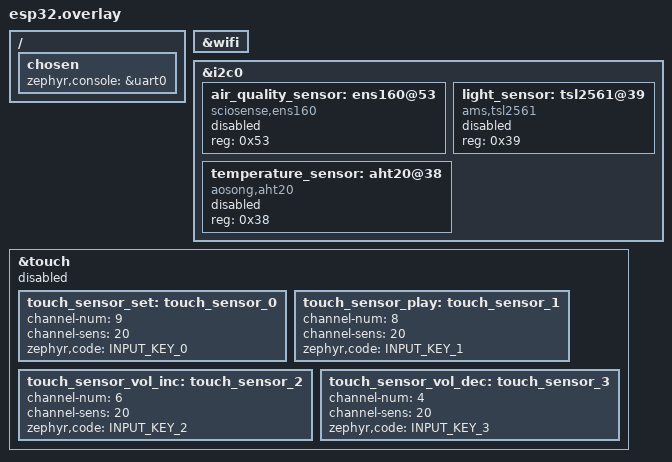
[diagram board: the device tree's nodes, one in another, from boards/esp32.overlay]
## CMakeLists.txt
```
#-------------------------------------------------------------------------------
# Zephyr Example Application
#
# Copyright (c) 2021 Nordic Semiconductor ASA
# SPDX-License-Identifier: Apache-2.0

cmake_minimum_required(VERSION 3.20.3)

#-------------------------------------------
# Overlay File
set(DTC_OVERLAY_FILE "boards/esp32.overlay")
set(CONFIG_APPLICATION_DEFINED_SYSCALL  TRUE)

# Define additional overlay configuration files
# set(OVERLAY_CONFIG "overlay-debug.conf; overlay-enterprise-variable-bufs.conf; overlay-enterprise.conf;")

# Pass configuration files to the build system
# set_property(GLOBAL PROPERTY OVERLAY_CONFIG "${OVERLAY_CONFIG}")

#-------------------------------------------
# Include Zephyr SDK
find_package(Zephyr REQUIRED HINTS $ENV{ZEPHYR_BASE})

#-------------------------------------------
# Project
project(app)

#-------------------------------------------
# Source Files
# Main
target_sources(app PRIVATE src/main.cpp)

# My Logger
target_sources(app PRIVATE src/myLogger/myLogger.cpp)

# Manager Factory
target_sources(app PRIVATE src/managerFactory/managerFactory.cpp)

# Network Manager
target_sources(app PRIVATE src/networkManager/networkManager.cpp)

# Network Time Manager
target_sources(app PRIVATE src/networkTimeManager/networkTimeManager.cpp)

# Ping Manager
target_sources(app PRIVATE src/pingManager/pingManager.cpp)

# Sensor Manager
target_sources(app PRIVATE src/sensorManager/sensorManager.cpp)

# Sensors
target_sources(app PRIVATE src/sensors/temperatureSensor.cpp)
target_sources(app PRIVATE src/sensors/lightSensor.cpp)

# Socket
target_sources(app PRIVATE src/sockets/sockets.cpp)

# Socket Manager
target_sources(app PRIVATE src/socketManager/socketManager.cpp)

# Socket Strategy
target_sources(app PRIVATE src/socketStrategy/socketStrategy.cpp)

# Wifi Manager
target_sources(app PRIVATE src/wifiManager/wifiManager.cpp)
target_sources(app PRIVATE src/wifiManager/wifiManagerHandlers.cpp)

# Wifi State Machine
target_sources(app PRIVATE src/wifiSM/wifiContext.cpp)
target_sources(app PRIVATE src/wifiSM/wifiStateConnected.cpp)
target_sources(app PRIVATE src/wifiSM/wifiStateConnecting.cpp)
target_sources(app PRIVATE src/wifiSM/wifiStateDisconnected.cpp)
target_sources(app PRIVATE src/wifiSM/wifiStateError.cpp)
target_sources(app PRIVATE src/wifiSM/wifiStateIdle.cpp)

#-------------------------------------------
# Include Directories
# zephyr_syscall_include_directories(./../include/app/drivers/)
# zephyr_include_directories(./../include)
# zephyr_include_directories(./../include/app/drivers/)

# My Logger
target_include_directories(app PRIVATE src/myLogger)

# Network Manager
target_include_directories(app PRIVATE src/networkManager)

# Network Time Manager
target_include_directories(app PRIVATE src/networkTimeManager)

# Ping Manager
target_include_directories(app PRIVATE src/pingManager)

# Sensor Manager
target_include_directories(app PRIVATE src/sensorManager)

# Sensors
target_include_directories(app PRIVATE src/sensors)

# Sockets
target_include_directories(app PRIVATE src/sockets)

# Socket Manager
target_include_directories(app PRIVATE src/socketManager)
target_include_directories(app PRIVATE src/socketStrategy)

# Wifi Manager
target_include_directories(app PRIVATE src/managerFactory)
target_include_directories(app PRIVATE src/wifiManager)
target_include_directories(app PRIVATE src/wifiSM)

target_include_directories(app PRIVATE ./../include/)
target_include_directories(app PRIVATE ./../include/app/)
target_include_directories(app PRIVATE ./../include/app/drivers)
# target_include_directories(app PRIVATE ./../include/utils/myLogger)

#-------------------------------------------
# System Calls Header Files
# zephyr_syscall_header_ifdef (./../include/app/drivers/my_syscall.h)
# zephyr_syscall_header (./../include/app/drivers/blink.h)

#-------------------------------------------
# Libraries
target_link_libraries(app PRIVATE zephyr_interface)

#-------------------------------------------
# Compiler Options
target_compile_definitions(app PRIVATE
    WIFI_SSID="$ENV{WIFI_SSID}"
    WIFI_PASSWORD="$ENV{WIFI_PASSWORD}"
    MY_REMOTE="$ENV{MY_REMOTE}"
    MY_LOCAL="$ENV{MY_LOCAL}"
)

#-------------------------------------------
# GraphViz
add_custom_target(graphviz
    COMMAND ${CMAKE_COMMAND} "--graphviz=dependencyGraph.dot" .
    WORKING_DIRECTORY "${CMAKE_BINARY_DIR}"
)
```

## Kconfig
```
# Copyright (c) 2021 Nordic Semiconductor ASA
# SPDX-License-Identifier: Apache-2.0
#
# This file is the application Kconfig entry point. All application Kconfig
# options can be defined here or included via other application Kconfig files.
# You can browse these options using the west targets menuconfig (terminal) or
# guiconfig (GUI).

# For Configuring Zephyr
menu "Zephyr"
source "Kconfig.zephyr"
endmenu

# For Configuring Custom Drivers/Libraries
menu "Custom Drivers/Libraries"
rsource "../Kconfig"
endmenu

# For Creating Logging Module for Application
module = APP
module-str = APP
source "subsys/logging/Kconfig.template.log_config"
```

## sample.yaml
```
# This file is provided so that the application can be compiled using Twister,
# the Zephyr testing tool. In this file, multiple combinations can be specified,
# so that you can easily test all of them locally or in CI.
sample:
  description: Example application
  name: example-application
common:
  build_only: true
  integration_platforms:
    - esp32
build:
  kconfig: Kconfig
  cmake: .
  board: esp32
  harness: net
  settings:
    board_root: boards/
    dts_root: .
  tags:
    - net
    - wifi
tests:
  sample.net.wifi.esp32:
    extra_args:
      - CONFIG_BUILD_ONLY_NO_BLOBS=y
  app.default: {}
  app.debug:
    extra_overlay_confs:
      - debug.conf
```

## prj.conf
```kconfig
# Enable Debugging
# CONFIG_DEBUG=y

# Power Management Configuration
# CONFIG_PM=y

# Required to disable default behavior of deep sleep on timeout
CONFIG_PM_DEVICE=y

# Sensor Configuration
CONFIG_SENSOR=y
CONFIG_I2C=y
CONFIG_AHT20=y
CONFIG_ENS160=y
CONFIG_GPIO=y

# CONFIG_INPUT_ESP32_TOUCH_SENSOR=y
# Enable CPP Support
CONFIG_CPP=y
CONFIG_STD_CPP20=y
CONFIG_GLIBCXX_LIBCPP=y
# following can be disabled to improve memory usage
# CONFIG_REQUIRES_FULL_LIBCPP=y
# CONFIG_STDOUT_CONSOLE=y
CONFIG_NEWLIB_LIBC=y

# Enable Syscalls Generation
# CONFIG_USERSPACE=y
# CONFIG_APPLICATION_DEFINED_SYSCALL=y
# CONFIG_EMIT_ALL_SYSCALLS=y

# WIFI Configuration
CONFIG_WIFI=y
CONFIG_ESP32_WIFI_STA_AUTO_DHCPV4=y
CONFIG_INIT_STACKS=y
CONFIG_NET_L2_WIFI_MGMT=y

# Networking Configuration
CONFIG_NETWORKING=y
CONFIG_NET_IPV4=y
CONFIG_NET_IPV6=y
CONFIG_NET_UDP=y
CONFIG_NET_TCP=y
CONFIG_NET_L2_ETHERNET=y
CONFIG_DNS_RESOLVER=y
CONFIG_DNS_RESOLVER_AI_MAX_ENTRIES=10

CONFIG_NET_MGMT_EVENT=y
# Added for ESP32 Pings not working
CONFIG_NET_ALLOW_ANY_PRIORITY=y

# Enable SNTP for Time Synchronization
CONFIG_SNTP=y
# CONFIG_SNTP_SERVER="pool.ntp.org"
# CONFIG_SNTP_INIT=y

# Enable Sockets
CONFIG_NET_SOCKETS=y
CONFIG_NET_SOCKETS_SOCKOPT_TLS=y
# Added for ESP32 Crashing during SNTP Query
CONFIG_NET_SOCKETS_POLL_MAX=4

CONFIG_HTTP_CLIENT=n

# Use DHCP for IPv4
CONFIG_NET_DHCPV4=y

# Enable Network Logging
CONFIG_NET_LOG=n
#CONFIG_WIFI_LOG_LEVEL_ERR=y
#CONFIG_NET_IPV6_LOG_LEVEL_DBG=y
#CONFIG_WIFI_LOG_LEVEL_INF=y

# Enable POSIX API
CONFIG_POSIX_API=y

# Enable Logging Messages
CONFIG_LOG=y
CONFIG_LOG_DEFAULT_LEVEL=3
CONFIG_LOG_MODE_IMMEDIATE=y
# CONFIG_KERNEL_LOG_LEVEL_DBG=y
# CONFIG_LOG_BUFFER_SIZE=4096
# CONFIG_LOG_MODE_DEFERRED=y

# Stack sizes
CONFIG_MAIN_STACK_SIZE=8192
CONFIG_SYSTEM_WORKQUEUE_STACK_SIZE=4096

# For ESP32 S3
CONFIG_NET_MGMT_EVENT_STACK_SIZE=2048
CONFIG_NET_TCP_WORKQ_STACK_SIZE=2048

CONFIG_NET_TX_STACK_SIZE=2048
CONFIG_NET_RX_STACK_SIZE=2048

CONFIG_NET_PKT_RX_COUNT=10
CONFIG_NET_PKT_TX_COUNT=10

CONFIG_NET_BUF_RX_COUNT=20
CONFIG_NET_BUF_TX_COUNT=20

CONFIG_NET_MAX_CONTEXTS=10

# Enable ESP32 Specific Configuration
CONFIG_HEAP_MEM_POOL_SIZE=65536
```

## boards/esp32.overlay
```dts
/*
 * Copyright (c) 2023 Espressif Systems (Shanghai) Co., Ltd.
 *
 * SPDX-License-Identifier: Apache-2.0
 */

#include <zephyr/dt-bindings/input/input-event-codes.h>
#include <zephyr/dt-bindings/input/esp32-touch-sensor-input.h>

/* Wifi Settings */
&wifi {
    status = "okay";
};

&i2c0 {
    air_quality_sensor: ens160@53 {
        compatible = "sciosense,ens160";
        reg = <0x53>;
        status = "disabled";
    };

    light_sensor: tsl2561@39 {
        compatible = "ams,tsl2561";
        reg = <0x39>;
        status = "disabled";
    };

    temperature_sensor: aht20@38 {
        compatible = "aosong,aht20";
        reg = <0x38>;
        status = "disabled";
    };
};

&touch {
    status = "disabled";

    touch_sensor_set: touch_sensor_0 {
        channel-num = <9>;
        channel-sens = <20>;
        zephyr,code = <INPUT_KEY_0>;
    };

    touch_sensor_play: touch_sensor_1 {
        channel-num = <8>;
        channel-sens = <20>;
        zephyr,code = <INPUT_KEY_1>;
    };

    touch_sensor_vol_inc: touch_sensor_2 {
        channel-num = <6>;
        channel-sens = <20>;
        zephyr,code = <INPUT_KEY_2>;
    };

    touch_sensor_vol_dec: touch_sensor_3 {
        channel-num = <4>;
        channel-sens = <20>;
        zephyr,code = <INPUT_KEY_3>;
    };
};

/{
    chosen{
        zephyr,console = &uart0;
    };
};
```

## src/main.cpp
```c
/*
 * This file is part of the Zephyr Home project.
 *
 * Copyright (C) 2024 Osama Salah-ud-din
 *
 * This program is free software: you can redistribute it and/or modify
 * it under the terms of the GNU Affero General Public License as published by
 * the Free Software Foundation, either version 3 of the License, or
 * (at your option) any later version.
 *
 * This program is distributed in the hope that it will be useful,
 * but WITHOUT ANY WARRANTY; without even the implied warranty of
 * MERCHANTABILITY or FITNESS FOR A PARTICULAR PURPOSE.  See the
 * GNU Affero General Public License for more details.
 *
 * You should have received a copy of the GNU Affero General Public License
 * along with this program.  If not, see <https://www.gnu.org/licenses/>.
 */
#include <zephyr/kernel.h>
#include <zephyr/logging/log.h>

#include <app_version.h>

LOG_MODULE_REGISTER(main, CONFIG_APP_LOG_LEVEL);

#include "myLogger.hpp"

#include "networkManager.hpp"
#include "networkTimeManager.hpp"
#include "socketManager.hpp"
#include "sockets.hpp"

#include "sensorManager.hpp"
#include "airQualitySensor.hpp"
#include "lightSensor.hpp"
#include "temperatureSensor.hpp"

#define STACK_SIZE (4096)
#define TASK_PRIORITY (-1)

K_THREAD_STACK_DEFINE(ntp_stack, STACK_SIZE);

static struct k_thread ntp_thread;

K_MUTEX_DEFINE(mutex);
K_CONDVAR_DEFINE(condvar);

static void ntp_sync_thread(void*, void*, void*)
{
    networkManager&     network = networkManager::getInstance();
    networkTimeManager& ntp     = networkTimeManager::getInstance();

    while (true)
    {
        if (network.isConnectedWAN())
        {
            ntp.tick();
            MYLOG("⏰ System Time Synced");
        }
        k_sleep(K_MINUTES(1));
    }
}

int main(void)
{
    /* Main Function */
    MYLOG("Hello World!");

    lightSensor       lightSensor;
    airQualitySensor  airQualitySensor;
    temperatureSensor temperatureSensor;

    sensorManager& sensorMgr = sensorManager::getInstance();

    sockets socketAirQualitySensor;
    sockets socketLightSensor;
    sockets socketTempSensor;

    networkManager& network = networkManager::getInstance();
    myLogger&       logger  = myLogger::getInstance();

    /* Initialize Network Manager */
    network.init();
    logger.init();
    sensorMgr.init();

    sensorMgr.add_sensor(&lightSensor, &socketLightSensor);
    sensorMgr.add_sensor(&airQualitySensor, &socketAirQualitySensor);
    sensorMgr.add_sensor(&temperatureSensor, &socketTempSensor);

    // socketLightSensor.open(networkManager::getInstance().getLocalServer(), portConfig::PORT_AIR_QUALITY_SENSOR,
    //                        socketManager::protocol::UDP);

    // socketLightSensor.open(networkManager::getInstance().getLocalServer(), portConfig::PORT_LIGHT_SENSOR,
    //                        socketManager::protocol::UDP);

    // socketLightSensor.open(networkManager::getInstance().getLocalServer(), portConfig::PORT_TEMP_SENSOR,
    //                        socketManager::protocol::UDP);

    bool isSocket =
        socketTempSensor.open(network.getLocalServer(), portConfig::PORT_TEMP_SENSOR, socketManager::protocol::UDP);
    if (!isSocket)
    {
        MYLOG(" Temperature Sensor Socket Initialization Failed: %d", isSocket);
    }

    isSocket = socketAirQualitySensor.open(network.getLocalServer(), portConfig::PORT_AIR_QUALITY_SENSOR,
                                           socketManager::protocol::UDP);
    if (!isSocket)
    {
        MYLOG(" Air Quality Sensor Socket Initialization Failed: %d", isSocket);
    }

    isSocket =
        socketLightSensor.open(network.getLocalServer(), portConfig::PORT_LIGHT_SENSOR, socketManager::protocol::UDP);
    if (!isSocket)
    {
        MYLOG(" Light Sensor Socket Initialization Failed: %d", isSocket);
    }

    uint64_t start = k_uptime_get();

    /* Create a Thread for SNTP Issue */
    k_thread_create(&ntp_thread, ntp_stack, K_THREAD_STACK_SIZEOF(ntp_stack), ntp_sync_thread, NULL, NULL, NULL,
                    TASK_PRIORITY, 0, K_NO_WAIT);

    while (true)
    {
        network.tick();

        if (network.isNetworkUp())
        {
            if (k_uptime_get() - start > 10000)
            {
                sensorMgr.tick();
                start = k_uptime_get();
                if (network.isConnectedLAN())
                {
                    MYLOG(" 💻 Connected to LAN");
                    if (isSocket)
                    {
                        MYLOG("Sent Data to local server. Return: %d", socketTempSensor.send("LAN", 4));
                    }
                }
                else
                {
                    MYLOG("Not connected to LAN");
                }
                if (network.isConnectedWAN())
                {
                    MYLOG("🌐 Connected to WAN");
                }
                else
                {
                    MYLOG("Not connected to WAN");
                }
            }
        }
    }
    return 0;
}
```
